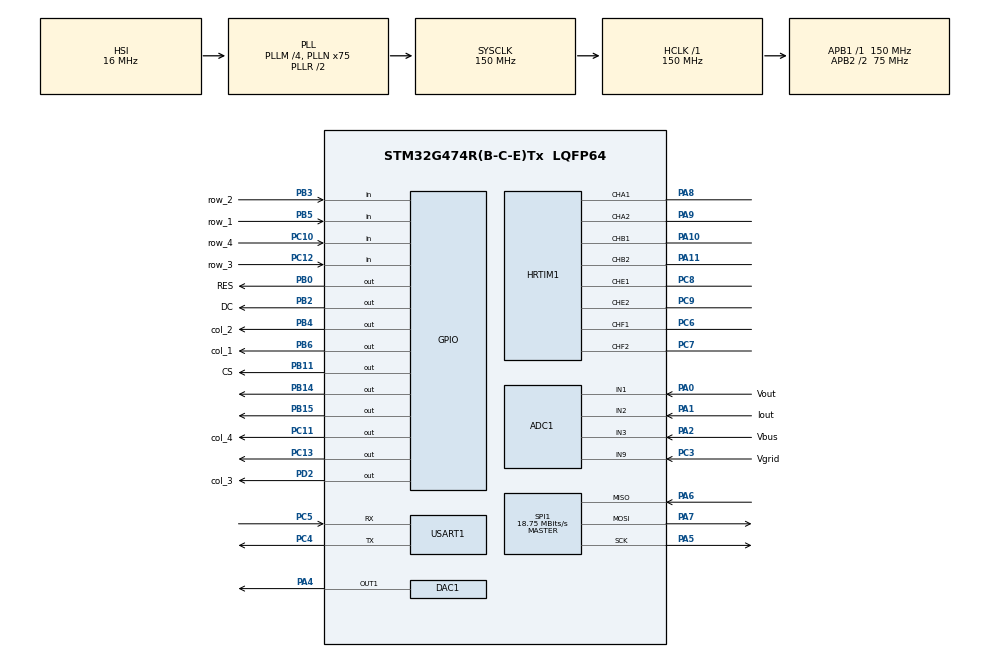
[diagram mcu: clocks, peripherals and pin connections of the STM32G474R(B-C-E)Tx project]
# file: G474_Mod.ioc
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ADC1.Channel-0\#ChannelRegularConversion=ADC_CHANNEL_1
ADC1.Channel-1\#ChannelRegularConversion=ADC_CHANNEL_2
ADC1.Channel-3\#ChannelRegularConversion=ADC_CHANNEL_3
ADC1.Channel-4\#ChannelRegularConversion=ADC_CHANNEL_9
ADC1.DMAContinuousRequests=ENABLE
ADC1.EnableInjectedConversion=DISABLE
ADC1.ExternalTrigConv=ADC_EXTERNALTRIG_HRTIM_TRG1
ADC1.NbrOfConversion=4
ADC1.NbrOfConversionFlag=1
ADC1.OffsetNumber-0\#ChannelRegularConversion=ADC_OFFSET_NONE
ADC1.OffsetNumber-1\#ChannelRegularConversion=ADC_OFFSET_NONE
ADC1.OffsetNumber-3\#ChannelRegularConversion=ADC_OFFSET_NONE
ADC1.OffsetNumber-4\#ChannelRegularConversion=ADC_OFFSET_NONE
ADC1.OversamplingMode=DISABLE
ADC1.Rank-0\#ChannelRegularConversion=1
ADC1.Rank-1\#ChannelRegularConversion=2
ADC1.Rank-3\#ChannelRegularConversion=3
ADC1.Rank-4\#ChannelRegularConversion=4
ADC1.SamplingTime-0\#ChannelRegularConversion=ADC_SAMPLETIME_47CYCLES_5
ADC1.SamplingTime-1\#ChannelRegularConversion=ADC_SAMPLETIME_47CYCLES_5
ADC1.SamplingTime-3\#ChannelRegularConversion=ADC_SAMPLETIME_6CYCLES_5
ADC1.SamplingTime-4\#ChannelRegularConversion=ADC_SAMPLETIME_6CYCLES_5
ADC1.master=1
Dma.ADC1.0.Direction=DMA_PERIPH_TO_MEMORY
Dma.ADC1.0.EventEnable=DISABLE
Dma.ADC1.0.Instance=DMA1_Channel1
Dma.ADC1.0.MemDataAlignment=DMA_MDATAALIGN_HALFWORD
Dma.ADC1.0.MemInc=DMA_MINC_ENABLE
Dma.ADC1.0.Mode=DMA_CIRCULAR
Dma.ADC1.0.PeriphDataAlignment=DMA_PDATAALIGN_HALFWORD
Dma.ADC1.0.PeriphInc=DMA_PINC_DISABLE
Dma.ADC1.0.Polarity=HAL_DMAMUX_REQ_GEN_RISING
Dma.ADC1.0.Priority=DMA_PRIORITY_LOW
Dma.ADC1.0.RequestNumber=1
Dma.ADC1.0.SignalID=NONE
Dma.ADC1.0.SyncEnable=DISABLE
Dma.ADC1.0.SyncPolarity=HAL_DMAMUX_SYNC_NO_EVENT
Dma.ADC1.0.SyncRequestNumber=1
Dma.ADC1.0.SyncSignalID=NONE
Dma.Request0=ADC1
HRTIM1.ADCTrigger1_Source1=HRTIM_ADCTRIGGEREVENT13_MASTER_CMP4
HRTIM1.ADCTrigger_Id1=HRTIM_ADCTRIGGER_1
HRTIM1.CompareUnit1-MasterTimer=HRTIM_COMPAREUNIT_1
HRTIM1.CompareUnit1-Output_TA1TA2=HRTIM_COMPAREUNIT_1
HRTIM1.CompareUnit4-MasterTimer=HRTIM_COMPAREUNIT_4
HRTIM1.CompareValue1-MasterTimer=2000
HRTIM1.CompareValue1-Output_TA1TA2=20000
HRTIM1.CompareValue4-MasterTimer=200
HRTIM1.IdleLevel2-Output_TA1TA2=HRTIM_OUTPUTIDLELEVEL_INACTIVE
HRTIM1.InterruptRequests1-Output_TA1TA2=HRTIM_TIM_IT_UPD
HRTIM1.NumberADCTriggerSource1=1
HRTIM1.NumberInterruptRequests-Output_TA1TA2=1
HRTIM1.NumberResetSource1-Output_TA1TA2=1
HRTIM1.NumberResetSource1-Output_TB1TB2=1
HRTIM1.NumberResetSource2_TA=1
HRTIM1.NumberResetSource2_TB=1
HRTIM1.NumberSetSource1-Output_TA1TA2=1
HRTIM1.NumberSetSource1-Output_TB1TB2=1
HRTIM1.NumberSetSource2_TA=1
HRTIM1.NumberSetSource2_TB=1
HRTIM1.Periode_MASTER=48000
HRTIM1.Periode_TA=40000
HRTIM1.Polarity2-Output_TA1TA2=HRTIM_OUTPUTPOLARITY_LOW
HRTIM1.Polarity2-Output_TB1TB2=HRTIM_OUTPUTPOLARITY_LOW
HRTIM1.PreloadEnable-MasterTimer=HRTIM_PRELOAD_ENABLED
HRTIM1.PreloadEnable-Output_TA1TA2=HRTIM_PRELOAD_ENABLED
HRTIM1.PreloadEnable-Output_TB1TB2=HRTIM_PRELOAD_ENABLED
HRTIM1.PrescalerRatio_MASTER=HRTIM_PRESCALERRATIO_MUL8
HRTIM1.RepetitionUpdate-MasterTimer=HRTIM_UPDATEONREPETITION_ENABLED
HRTIM1.RepetitionUpdate-Output_TA1TA2=HRTIM_UPDATEONREPETITION_ENABLED
HRTIM1.RepetitionUpdate-Output_TB1TB2=HRTIM_UPDATEONREPETITION_ENABLED
HRTIM1.ResetOutput1_Source1-Output_TA1TA2=HRTIM_OUTPUTRESET_MASTERCMP1
HRTIM1.ResetOutput1_Source1-Output_TB1TB2=HRTIM_OUTPUTRESET_MASTERPER
HRTIM1.ResetOutput2_Source1-Output_TA1TA2=HRTIM_OUTPUTRESET_MASTERPER
HRTIM1.ResetOutput2_Source1-Output_TB1TB2=HRTIM_OUTPUTRESET_MASTERCMP1
HRTIM1.SetOutput1_Source1-Output_TA1TA2=HRTIM_OUTPUTSET_MASTERPER
HRTIM1.SetOutput1_Source1-Output_TB1TB2=HRTIM_OUTPUTSET_MASTERCMP1
HRTIM1.SetOutput2_Source1-Output_TA1TA2=HRTIM_OUTPUTSET_MASTERCMP1
HRTIM1.SetOutput2_Source1-Output_TB1TB2=HRTIM_OUTPUTSET_MASTERPER
HRTIM1.SyncOptions=HRTIM_SYNCOPTION_SLAVE
Mcu.Family=STM32G4
Mcu.Name=STM32G474R(B-C-E)Tx
Mcu.Package=LQFP64
NVIC.ADC1_2_IRQn=true\:0\:0\:false\:false\:true\:true\:true\:true
NVIC.DMA1_Channel1_IRQn=true\:0\:0\:false\:false\:true\:false\:true\:true
NVIC.PriorityGroup=NVIC_PRIORITYGROUP_4
PA0.GPIO_Label=Vout
PA0.Mode=IN1-Single-Ended
PA0.Signal=ADC1_IN1
PA1.GPIO_Label=Iout
PA1.Mode=IN2-Single-Ended
PA1.Signal=ADC1_IN2
PA10.Mode=Output_TB1TB2
PA10.Signal=HRTIM1_CHB1
PA11.Mode=Output_TB1TB2
PA11.Signal=HRTIM1_CHB2
PA13.Mode=Serial_Wire
PA13.Signal=SYS_JTMS-SWDIO
PA14.Mode=Serial_Wire
PA14.Signal=SYS_JTCK-SWCLK
PA2.GPIO_Label=Vbus
PA2.Mode=IN3-Single-Ended
PA2.Signal=ADC1_IN3
PA4.Signal=COMP_DAC11_group
PA5.Mode=Full_Duplex_Master
PA5.Signal=SPI1_SCK
PA6.Mode=Full_Duplex_Master
PA6.Signal=SPI1_MISO
PA7.Mode=Full_Duplex_Master
PA7.Signal=SPI1_MOSI
PA8.Mode=Output_TA1TA2
PA8.Signal=HRTIM1_CHA1
PA9.Mode=Output_TA1TA2
PA9.Signal=HRTIM1_CHA2
PB0.GPIO_Label=RES
PB0.Signal=GPIO_Output
PB11.GPIO_Label=CS
PB11.Signal=GPIO_Output
PB14.Signal=GPIO_Output
PB15.GPIO_PuPd=GPIO_NOPULL
PB15.Signal=GPIO_Output
PB2.GPIO_Label=DC
PB2.Signal=GPIO_Output
PB3.GPIO_Label=row_2
PB3.GPIO_PuPd=GPIO_PULLDOWN
PB3.Signal=GPIO_Input
PB4.GPIO_Label=col_2
PB4.GPIO_PuPd=GPIO_PULLUP
PB4.Signal=GPIO_Output
PB5.GPIO_Label=row_1
PB5.GPIO_PuPd=GPIO_PULLDOWN
PB5.Signal=GPIO_Input
PB6.GPIO_Label=col_1
PB6.GPIO_PuPd=GPIO_PULLUP
PB6.Signal=GPIO_Output
PC10.GPIO_Label=row_4
PC10.GPIO_PuPd=GPIO_PULLDOWN
PC10.Signal=GPIO_Input
PC11.GPIO_Label=col_4
PC11.GPIO_PuPd=GPIO_PULLUP
PC11.Signal=GPIO_Output
PC12.GPIO_Label=row_3
PC12.GPIO_PuPd=GPIO_PULLDOWN
PC12.Signal=GPIO_Input
PC13.Signal=GPIO_Output
PC3.GPIO_Label=Vgrid
PC3.Mode=IN9-Single-Ended
PC3.Signal=ADC1_IN9
PC4.Mode=Asynchronous
PC4.Signal=USART1_TX
PC5.Mode=Asynchronous
PC5.Signal=USART1_RX
PC6.Mode=Output_TF1TF2
PC6.Signal=HRTIM1_CHF1
PC7.Mode=Output_TF1TF2
PC7.Signal=HRTIM1_CHF2
PC8.Mode=Output_TE1TE2
PC8.Signal=HRTIM1_CHE1
PC9.Mode=Output_TE1TE2
PC9.Signal=HRTIM1_CHE2
PD2.GPIO_Label=col_3
PD2.GPIO_PuPd=GPIO_PULLUP
PD2.Signal=GPIO_Output
PF0-OSC_IN.Mode=HSE-External-Oscillator
PF0-OSC_IN.Signal=RCC_OSC_IN
PF1-OSC_OUT.Mode=HSE-External-Oscillator
PF1-OSC_OUT.Signal=RCC_OSC_OUT
ProjectManager.HeapSize=0x200
ProjectManager.StackSize=0x400
ProjectManager.TargetToolchain=Makefile
RCC.ADC12Freq_Value=150000000
RCC.ADC345Freq_Value=150000000
RCC.AHBFreq_Value=150000000
RCC.APB1Freq_Value=150000000
RCC.APB1TimFreq_Value=150000000
RCC.APB2CLKDivider=RCC_HCLK_DIV2
RCC.APB2Freq_Value=75000000
RCC.APB2TimFreq_Value=150000000
RCC.CortexFreq_Value=150000000
RCC.EXTERNAL_CLOCK_VALUE=12288000
RCC.HCLKFreq_Value=150000000
RCC.HSE_VALUE=8000000
RCC.HSI48_VALUE=48000000
RCC.HSI_VALUE=16000000
RCC.LSE_VALUE=32768
RCC.PLLM=RCC_PLLM_DIV4
RCC.PLLN=75
RCC.SYSCLKFreq_VALUE=150000000
RCC.SYSCLKSource=RCC_SYSCLKSOURCE_PLLCLK
RCC.USBFreq_Value=150000000
RCC.VCOOutputFreq_Value=300000000
SH.COMP_DAC11_group.0=DAC1_OUT1,DAC_OUT1
SPI1.BaudRatePrescaler=SPI_BAUDRATEPRESCALER_4
SPI1.CalculateBaudRate=18.75 MBits/s
SPI1.DataSize=SPI_DATASIZE_8BIT
SPI1.Direction=SPI_DIRECTION_2LINES
SPI1.Mode=SPI_MODE_MASTER
SPI1.NSSPMode=SPI_NSS_PULSE_DISABLE
SPI1.VirtualType=VM_MASTER
STMicroelectronics.X-CUBE-ALGOBUILD.1.3.0.LibraryCcDSPOoLibraryJjDSPOoLibrary=true
USART1.VirtualMode-Asynchronous=VM_ASYNC
VP_HRTIM1_VS_hrtimMasterTimerNoOutput.Mode=MasterTimer
VP_STMicroelectronics.X-CUBE-ALGOBUILD_VS_DSPOoLibraryJjLibrary_1.3.0_1.3.0.Mode=DSPOoLibraryJjLibrary
VP_SYS_VS_DBSignals.Mode=DisableDeadBatterySignals
board=custom

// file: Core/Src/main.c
/* USER CODE BEGIN Header */
/**
  ******************************************************************************
  * @file           : main.c
  * @brief          : Main program body
  ******************************************************************************
  * @attention
  *
  * Copyright (c) 2023 STMicroelectronics.
  * All rights reserved.
  *
  * This software is licensed under terms that can be found in the LICENSE file
  * in the root directory of this software component.
  * If no LICENSE file comes with this software, it is provided AS-IS.
  *
  ******************************************************************************
  */
/* USER CODE END Header */
#include "main.h"
#include "adc.h"
#include "dac.h"
#include "dma.h"
#include "hrtim.h"
#include "spi.h"
#include "usart.h"
#include "gpio.h"

/* USER CODE BEGIN Includes */
#include "inc.h"
#include "arm_math.h"
/* USER CODE END Includes */

void SystemClock_Config(void);

int main(void)
{

  /* MCU Configuration--------------------------------------------------------*/

  /* Reset of all peripherals, Initializes the Flash interface and the Systick. */
      HAL_Init();

  /* Configure the system clock */
  SystemClock_Config();

  /* Initialize all configured peripherals */
  MX_GPIO_Init();
  MX_DMA_Init();
  MX_SPI1_Init();
  MX_ADC1_Init();
  MX_USART1_UART_Init();
  MX_HRTIM1_Init();
  MX_DAC1_Init();
  /* USER CODE BEGIN 2 */
  //__HAL_SPI_ENABLE(&hspi1);
  Task_Init();

  /* USER CODE END 2 */

  /* Infinite loop */
  while (1)
  {

    /* USER CODE BEGIN 3 */

    //keyboard_execute();
    Task_Do();

  }
  /* USER CODE END 3 */
}

void SystemClock_Config(void)
{
  RCC_OscInitTypeDef RCC_OscInitStruct = {0};
  RCC_ClkInitTypeDef RCC_ClkInitStruct = {0};

  /** Configure the main internal regulator output voltage
  */
  HAL_PWREx_ControlVoltageScaling(PWR_REGULATOR_VOLTAGE_SCALE1);

  /** Initializes the RCC Oscillators according to the specified parameters
  * in the RCC_OscInitTypeDef structure.
  */
  RCC_OscInitStruct.OscillatorType = RCC_OSCILLATORTYPE_HSI;
  RCC_OscInitStruct.HSIState = RCC_HSI_ON;
  RCC_OscInitStruct.HSICalibrationValue = RCC_HSICALIBRATION_DEFAULT;
  RCC_OscInitStruct.PLL.PLLState = RCC_PLL_ON;
  RCC_OscInitStruct.PLL.PLLSource = RCC_PLLSOURCE_HSI;
  RCC_OscInitStruct.PLL.PLLM = RCC_PLLM_DIV4;
  RCC_OscInitStruct.PLL.PLLN = 75;
  RCC_OscInitStruct.PLL.PLLP = RCC_PLLP_DIV2;
  RCC_OscInitStruct.PLL.PLLQ = RCC_PLLQ_DIV2;
  RCC_OscInitStruct.PLL.PLLR = RCC_PLLR_DIV2;
  if (HAL_RCC_OscConfig(&RCC_OscInitStruct) != HAL_OK)
  {
    Error_Handler();
  }

  /** Initializes the CPU, AHB and APB buses clocks
  */
  RCC_ClkInitStruct.ClockType = RCC_CLOCKTYPE_HCLK|RCC_CLOCKTYPE_SYSCLK
                              |RCC_CLOCKTYPE_PCLK1|RCC_CLOCKTYPE_PCLK2;
  RCC_ClkInitStruct.SYSCLKSource = RCC_SYSCLKSOURCE_PLLCLK;
  RCC_ClkInitStruct.AHBCLKDivider = RCC_SYSCLK_DIV1;
  RCC_ClkInitStruct.APB1CLKDivider = RCC_HCLK_DIV1;
  RCC_ClkInitStruct.APB2CLKDivider = RCC_HCLK_DIV2;

  if (HAL_RCC_ClockConfig(&RCC_ClkInitStruct, FLASH_LATENCY_4) != HAL_OK)
  {
    Error_Handler();
  }
}

void Error_Handler(void)
{
  __disable_irq();
  while (1)
  {
  }
}
